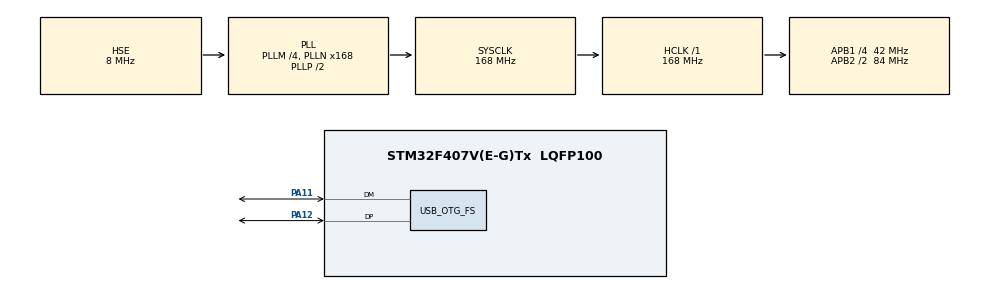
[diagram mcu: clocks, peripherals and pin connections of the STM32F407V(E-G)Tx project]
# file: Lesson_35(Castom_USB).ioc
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Mcu.Family=STM32F4
Mcu.Name=STM32F407V(E-G)Tx
Mcu.Package=LQFP100
NVIC.OTG_FS_IRQn=true\:0\:0\:false\:false\:true
NVIC.PriorityGroup=NVIC_PRIORITYGROUP_4
NVIC.TIM6_DAC_IRQn=true\:0\:0\:false\:false\:true
PA11.Mode=Device_Only
PA11.Signal=USB_OTG_FS_DM
PA12.Mode=Device_Only
PA12.Signal=USB_OTG_FS_DP
PH0-OSC_IN.Mode=HSE-External-Oscillator
PH0-OSC_IN.Signal=RCC_OSC_IN
PH1-OSC_OUT.Mode=HSE-External-Oscillator
PH1-OSC_OUT.Signal=RCC_OSC_OUT
ProjectManager.HeapSize=0x200
ProjectManager.StackSize=0x400
ProjectManager.TargetToolchain=MDK-ARM V5
RCC.48MHZClocksFreq_Value=48000000
RCC.AHBFreq_Value=168000000
RCC.APB1CLKDivider=RCC_HCLK_DIV4
RCC.APB1Freq_Value=42000000
RCC.APB1TimFreq_Value=84000000
RCC.APB2CLKDivider=RCC_HCLK_DIV2
RCC.APB2Freq_Value=84000000
RCC.APB2TimFreq_Value=168000000
RCC.CortexFreq_Value=168000000
RCC.HCLKFreq_Value=168000000
RCC.HSE_VALUE=8000000
RCC.HSI_VALUE=16000000
RCC.LSE_VALUE=32768
RCC.PLLM=4
RCC.PLLN=168
RCC.PLLQ=7
RCC.SYSCLKFreq_VALUE=168000000
RCC.SYSCLKSource=RCC_SYSCLKSOURCE_PLLCLK
RCC.VCOOutputFreq_Value=336000000
TIM6.Period=1000
TIM6.Prescaler=41999
TIM6.TIM_MasterOutputTrigger=TIM_TRGO_UPDATE
USB_DEVICE.CLASS_NAME_FS=CUSTOMHID
USB_DEVICE.VirtualModeFS=Custom_Hid_FS
USB_OTG_FS.VirtualMode=Device_Only
VP_TIM6_VS_ClockSourceINT.Mode=Enable_Timer
VP_USB_DEVICE_VS_USB_DEVICE_CUSTOM_HID_FS.Mode=CUSTOM_HID_FS
board=Lesson_35(Castom_USB)

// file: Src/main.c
#include "main.h"
#include "stm32f4xx_hal.h"
#include "usb_device.h"
#include "usbd_customhid.h"

TIM_HandleTypeDef htim6;

/* USER CODE BEGIN PV */
/* Private variables ---------------------------------------------------------*/
extern USBD_HandleTypeDef  hUsbDeviceFS;
uint8_t dataToSend[5];
uint8_t btn_stat=0;
/* USER CODE END PV */

void SystemClock_Config(void);
void Error_Handler(void);
static void MX_GPIO_Init(void);
static void MX_TIM6_Init(void);

/* USER CODE BEGIN PFP */
/* Private function prototypes -----------------------------------------------*/

/* USER CODE END PFP */

int main(void)
{

  /* MCU Configuration----------------------------------------------------------*/

  /* Reset of all peripherals, Initializes the Flash interface and the Systick. */
  HAL_Init();

  /* Configure the system clock */
  SystemClock_Config();

  /* Initialize all configured peripherals */
  MX_GPIO_Init();
  MX_TIM6_Init();
  MX_USB_DEVICE_Init();
	HAL_TIM_Base_Start_IT(&htim6);

 HAL_GPIO_WritePin(GPIOD,GPIO_PIN_12,GPIO_PIN_SET);
  while (1)
  {
  /* USER CODE END WHILE */

  }

}

/** System Clock Configuration
*/
void SystemClock_Config(void)
{

  RCC_OscInitTypeDef RCC_OscInitStruct;
  RCC_ClkInitTypeDef RCC_ClkInitStruct;

    /**Configure the main internal regulator output voltage
    */
  __HAL_RCC_PWR_CLK_ENABLE();

  __HAL_PWR_VOLTAGESCALING_CONFIG(PWR_REGULATOR_VOLTAGE_SCALE1);

    /**Initializes the CPU, AHB and APB busses clocks
    */
  RCC_OscInitStruct.OscillatorType = RCC_OSCILLATORTYPE_HSE;
  RCC_OscInitStruct.HSEState = RCC_HSE_ON;
  RCC_OscInitStruct.PLL.PLLState = RCC_PLL_ON;
  RCC_OscInitStruct.PLL.PLLSource = RCC_PLLSOURCE_HSE;
  RCC_OscInitStruct.PLL.PLLM = 4;
  RCC_OscInitStruct.PLL.PLLN = 168;
  RCC_OscInitStruct.PLL.PLLP = RCC_PLLP_DIV2;
  RCC_OscInitStruct.PLL.PLLQ = 7;
  if (HAL_RCC_OscConfig(&RCC_OscInitStruct) != HAL_OK)
  {
    Error_Handler();
  }

    /**Initializes the CPU, AHB and APB busses clocks
    */
  RCC_ClkInitStruct.ClockType = RCC_CLOCKTYPE_HCLK|RCC_CLOCKTYPE_SYSCLK
                              |RCC_CLOCKTYPE_PCLK1|RCC_CLOCKTYPE_PCLK2;
  RCC_ClkInitStruct.SYSCLKSource = RCC_SYSCLKSOURCE_PLLCLK;
  RCC_ClkInitStruct.AHBCLKDivider = RCC_SYSCLK_DIV1;
  RCC_ClkInitStruct.APB1CLKDivider = RCC_HCLK_DIV4;
  RCC_ClkInitStruct.APB2CLKDivider = RCC_HCLK_DIV2;

  if (HAL_RCC_ClockConfig(&RCC_ClkInitStruct, FLASH_LATENCY_5) != HAL_OK)
  {
    Error_Handler();
  }

    /**Configure the Systick interrupt time
    */
  HAL_SYSTICK_Config(HAL_RCC_GetHCLKFreq()/1000);

    /**Configure the Systick
    */
  HAL_SYSTICK_CLKSourceConfig(SYSTICK_CLKSOURCE_HCLK);

  /* SysTick_IRQn interrupt configuration */
  HAL_NVIC_SetPriority(SysTick_IRQn, 0, 0);
}

/* TIM6 init function */
static void MX_TIM6_Init(void)
{

  TIM_MasterConfigTypeDef sMasterConfig;

  htim6.Instance = TIM6;
  htim6.Init.Prescaler = 41999;
  htim6.Init.CounterMode = TIM_COUNTERMODE_UP;
  htim6.Init.Period = 1000;
  if (HAL_TIM_Base_Init(&htim6) != HAL_OK)
  {
    Error_Handler();
  }

  sMasterConfig.MasterOutputTrigger = TIM_TRGO_UPDATE;
  sMasterConfig.MasterSlaveMode = TIM_MASTERSLAVEMODE_DISABLE;
  if (HAL_TIMEx_MasterConfigSynchronization(&htim6, &sMasterConfig) != HAL_OK)
  {
    Error_Handler();
  }

}

/** Configure pins as
        * Analog
        * Input
        * Output
        * EVENT_OUT
        * EXTI
*/
static void MX_GPIO_Init(void)
{

  /* GPIO Ports Clock Enable */
  __HAL_RCC_GPIOH_CLK_ENABLE();
  __HAL_RCC_GPIOA_CLK_ENABLE();

	/*Configure GPIO pin Output Level */
 // HAL_GPIO_WritePin(GPIOD, GPIO_PIN_12|GPIO_PIN_13|GPIO_PIN_14|GPIO_PIN_15, GPIO_PIN_RESET);

}

/* USER CODE BEGIN 4 */
void HAL_TIM_PeriodElapsedCallback(TIM_HandleTypeDef *htim6)
{
	  if(btn_stat==0)        {dataToSend[0] = 6;dataToSend[1] = 1;}
        else if(btn_stat==1)        {dataToSend[0] = 6;dataToSend[1] = 0;}
        else if(btn_stat==2)        {dataToSend[0] = 5;dataToSend[1] = 1;}
        else if(btn_stat==3)        {dataToSend[0] = 5;dataToSend[1] = 0;}
        dataToSend[2] = 'H';
				dataToSend[3] = 'I';
        dataToSend[4] = 'D';
  USBD_CUSTOM_HID_SendReport(&hUsbDeviceFS, dataToSend, 5);
        btn_stat++;
        if(btn_stat>3) btn_stat=0;
}
/* USER CODE END 4 */

void Error_Handler(void)
{
  while(1)
  {
  }
}

/************************ (C) COPYRIGHT STMicroelectronics *****END OF FILE****/
